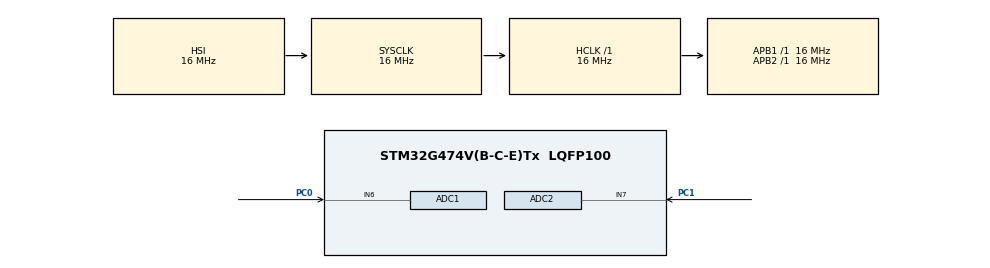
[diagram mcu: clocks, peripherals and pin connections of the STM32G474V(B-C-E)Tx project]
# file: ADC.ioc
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ADC1.Channel-0\#ChannelRegularConversion=ADC_CHANNEL_6
ADC1.DiscontinuousConvMode=DISABLE
ADC1.Mode=ADC_DUALMODE_REGSIMULT
ADC1.NbrOfConversion=1
ADC1.NbrOfConversionFlag=1
ADC1.OffsetNumber-0\#ChannelRegularConversion=ADC_OFFSET_NONE
ADC1.Rank-0\#ChannelRegularConversion=1
ADC1.SamplingTime-0\#ChannelRegularConversion=ADC_SAMPLETIME_640CYCLES_5
ADC1.master=1
ADC2.Channel-0\#ChannelRegularConversion=ADC_CHANNEL_7
ADC2.Mode=ADC_DUALMODE_REGSIMULT
ADC2.NbrOfConversionFlag=1
ADC2.OffsetNumber-0\#ChannelRegularConversion=ADC_OFFSET_NONE
ADC2.Rank-0\#ChannelRegularConversion=1
ADC2.SamplingTime-0\#ChannelRegularConversion=ADC_SAMPLETIME_640CYCLES_5
Mcu.Family=STM32G4
Mcu.Name=STM32G474V(B-C-E)Tx
Mcu.Package=LQFP100
NVIC.PriorityGroup=NVIC_PRIORITYGROUP_4
PC0.Mode=IN6-Single-Ended
PC0.Signal=ADC1_IN6
PC1.Mode=IN7-Single-Ended
PC1.Signal=ADC2_IN7
ProjectManager.HeapSize=0x200
ProjectManager.StackSize=0x400
ProjectManager.TargetToolchain=STM32CubeIDE
RCC.AHBFreq_Value=16000000
RCC.APB1Freq_Value=16000000
RCC.APB1TimFreq_Value=16000000
RCC.APB2Freq_Value=16000000
RCC.APB2TimFreq_Value=16000000
RCC.CortexFreq_Value=16000000
RCC.EXTERNAL_CLOCK_VALUE=12288000
RCC.HCLKFreq_Value=16000000
RCC.HSE_VALUE=8000000
RCC.HSI48_VALUE=48000000
RCC.HSI_VALUE=16000000
RCC.LSE_VALUE=32768
RCC.SYSCLKFreq_VALUE=16000000
RCC.USBFreq_Value=64000000
RCC.VCOOutputFreq_Value=128000000
VP_SYS_VS_DBSignals.Mode=DisableDeadBatterySignals
board=custom

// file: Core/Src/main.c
/* USER CODE BEGIN Header */
/**
  ******************************************************************************
  * @file           : main.c
  * @brief          : Main program body
  ******************************************************************************
  * @attention
  *
  * Copyright (c) 2025 STMicroelectronics.
  * All rights reserved.
  *
  * This software is licensed under terms that can be found in the LICENSE file
  * in the root directory of this software component.
  * If no LICENSE file comes with this software, it is provided AS-IS.
  *
  ******************************************************************************
  */
/* USER CODE END Header */
#include "main.h"

ADC_HandleTypeDef hadc1;
ADC_HandleTypeDef hadc2;

void SystemClock_Config(void);
static void MX_GPIO_Init(void);
static void MX_ADC1_Init(void);
static void MX_ADC2_Init(void);

/* USER CODE BEGIN 0 */
uint16_t result_x = 0;
uint16_t result_y = 0;
/* USER CODE END 0 */

int main(void)
{

  /* MCU Configuration--------------------------------------------------------*/

  /* Reset of all peripherals, Initializes the Flash interface and the Systick. */
  HAL_Init();

  /* Configure the system clock */
  SystemClock_Config();

  /* Initialize all configured peripherals */
  MX_GPIO_Init();
  MX_ADC1_Init();
  MX_ADC2_Init();

  /* Infinite loop */
  while (1)
  {

    /* USER CODE BEGIN 3 */
//  	HAL_ADC_Start(&hadc1);
//  	HAL_ADC_Start(&hadc2);
//
//  	HAL_ADC_PollForConversion(&hadc1, 10);
//  	result_x = HAL_ADC_GetValue(&hadc1);
//
//  	HAL_ADC_Start(&hadc1);
//  	HAL_ADC_PollForConversion(&hadc1, 10);
//  	result_y = HAL_ADC_GetValue(&hadc1);
//  	HAL_ADC_Stop(&hadc1);
//  	HAL_Delay(99);
  	HAL_ADC_Start(&hadc2);
  	HAL_ADC_Start(&hadc1);

  	HAL_ADC_PollForConversion(&hadc1, 10);
  	result_x = HAL_ADC_GetValue(&hadc1);
  	result_y = HAL_ADC_GetValue(&hadc2);

  	HAL_ADC_Stop(&hadc1);
  	HAL_ADC_Stop(&hadc2);
  	HAL_Delay(99);
  }
  /* USER CODE END 3 */
}

void SystemClock_Config(void)
{
  RCC_OscInitTypeDef RCC_OscInitStruct = {0};
  RCC_ClkInitTypeDef RCC_ClkInitStruct = {0};

  /** Configure the main internal regulator output voltage
  */
  HAL_PWREx_ControlVoltageScaling(PWR_REGULATOR_VOLTAGE_SCALE1);

  /** Initializes the RCC Oscillators according to the specified parameters
  * in the RCC_OscInitTypeDef structure.
  */
  RCC_OscInitStruct.OscillatorType = RCC_OSCILLATORTYPE_HSI;
  RCC_OscInitStruct.HSIState = RCC_HSI_ON;
  RCC_OscInitStruct.HSICalibrationValue = RCC_HSICALIBRATION_DEFAULT;
  RCC_OscInitStruct.PLL.PLLState = RCC_PLL_NONE;
  if (HAL_RCC_OscConfig(&RCC_OscInitStruct) != HAL_OK)
  {
    Error_Handler();
  }

  /** Initializes the CPU, AHB and APB buses clocks
  */
  RCC_ClkInitStruct.ClockType = RCC_CLOCKTYPE_HCLK|RCC_CLOCKTYPE_SYSCLK
                              |RCC_CLOCKTYPE_PCLK1|RCC_CLOCKTYPE_PCLK2;
  RCC_ClkInitStruct.SYSCLKSource = RCC_SYSCLKSOURCE_HSI;
  RCC_ClkInitStruct.AHBCLKDivider = RCC_SYSCLK_DIV1;
  RCC_ClkInitStruct.APB1CLKDivider = RCC_HCLK_DIV1;
  RCC_ClkInitStruct.APB2CLKDivider = RCC_HCLK_DIV1;

  if (HAL_RCC_ClockConfig(&RCC_ClkInitStruct, FLASH_LATENCY_0) != HAL_OK)
  {
    Error_Handler();
  }
}

static void MX_ADC1_Init(void)
{

  ADC_MultiModeTypeDef multimode = {0};
  ADC_ChannelConfTypeDef sConfig = {0};

  /** Common config
  */
  hadc1.Instance = ADC1;
  hadc1.Init.ClockPrescaler = ADC_CLOCK_SYNC_PCLK_DIV2;
  hadc1.Init.Resolution = ADC_RESOLUTION_12B;
  hadc1.Init.DataAlign = ADC_DATAALIGN_RIGHT;
  hadc1.Init.GainCompensation = 0;
  hadc1.Init.ScanConvMode = ADC_SCAN_DISABLE;
  hadc1.Init.EOCSelection = ADC_EOC_SINGLE_CONV;
  hadc1.Init.LowPowerAutoWait = DISABLE;
  hadc1.Init.ContinuousConvMode = DISABLE;
  hadc1.Init.NbrOfConversion = 1;
  hadc1.Init.DiscontinuousConvMode = DISABLE;
  hadc1.Init.ExternalTrigConv = ADC_SOFTWARE_START;
  hadc1.Init.ExternalTrigConvEdge = ADC_EXTERNALTRIGCONVEDGE_NONE;
  hadc1.Init.DMAContinuousRequests = DISABLE;
  hadc1.Init.Overrun = ADC_OVR_DATA_PRESERVED;
  hadc1.Init.OversamplingMode = DISABLE;
  if (HAL_ADC_Init(&hadc1) != HAL_OK)
  {
    Error_Handler();
  }

  /** Configure the ADC multi-mode
  */
  multimode.Mode = ADC_DUALMODE_REGSIMULT;
  multimode.DMAAccessMode = ADC_DMAACCESSMODE_DISABLED;
  multimode.TwoSamplingDelay = ADC_TWOSAMPLINGDELAY_1CYCLE;
  if (HAL_ADCEx_MultiModeConfigChannel(&hadc1, &multimode) != HAL_OK)
  {
    Error_Handler();
  }

  /** Configure Regular Channel
  */
  sConfig.Channel = ADC_CHANNEL_6;
  sConfig.Rank = ADC_REGULAR_RANK_1;
  sConfig.SamplingTime = ADC_SAMPLETIME_640CYCLES_5;
  sConfig.SingleDiff = ADC_SINGLE_ENDED;
  sConfig.OffsetNumber = ADC_OFFSET_NONE;
  sConfig.Offset = 0;
  if (HAL_ADC_ConfigChannel(&hadc1, &sConfig) != HAL_OK)
  {
    Error_Handler();
  }

}

static void MX_ADC2_Init(void)
{

  ADC_ChannelConfTypeDef sConfig = {0};

  /** Common config
  */
  hadc2.Instance = ADC2;
  hadc2.Init.ClockPrescaler = ADC_CLOCK_SYNC_PCLK_DIV2;
  hadc2.Init.Resolution = ADC_RESOLUTION_12B;
  hadc2.Init.DataAlign = ADC_DATAALIGN_RIGHT;
  hadc2.Init.GainCompensation = 0;
  hadc2.Init.ScanConvMode = ADC_SCAN_DISABLE;
  hadc2.Init.EOCSelection = ADC_EOC_SINGLE_CONV;
  hadc2.Init.LowPowerAutoWait = DISABLE;
  hadc2.Init.ContinuousConvMode = DISABLE;
  hadc2.Init.NbrOfConversion = 1;
  hadc2.Init.DiscontinuousConvMode = DISABLE;
  hadc2.Init.DMAContinuousRequests = DISABLE;
  hadc2.Init.Overrun = ADC_OVR_DATA_PRESERVED;
  hadc2.Init.OversamplingMode = DISABLE;
  if (HAL_ADC_Init(&hadc2) != HAL_OK)
  {
    Error_Handler();
  }

  /** Configure Regular Channel
  */
  sConfig.Channel = ADC_CHANNEL_7;
  sConfig.Rank = ADC_REGULAR_RANK_1;
  sConfig.SamplingTime = ADC_SAMPLETIME_640CYCLES_5;
  sConfig.SingleDiff = ADC_SINGLE_ENDED;
  sConfig.OffsetNumber = ADC_OFFSET_NONE;
  sConfig.Offset = 0;
  if (HAL_ADC_ConfigChannel(&hadc2, &sConfig) != HAL_OK)
  {
    Error_Handler();
  }

}

static void MX_GPIO_Init(void)
{

  /* GPIO Ports Clock Enable */
  __HAL_RCC_GPIOC_CLK_ENABLE();

}

void Error_Handler(void)
{
  __disable_irq();
  while (1)
  {
  }
}
